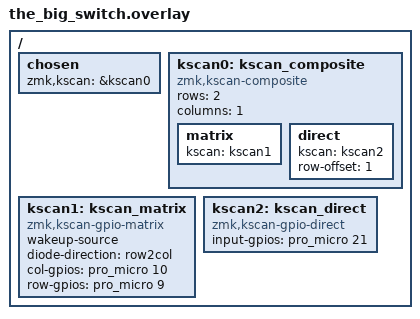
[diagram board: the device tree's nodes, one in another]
/*
 * Copyright (c) 2022 The ZMK Contributors
 *
 * SPDX-License-Identifier: MIT
 */

/ {
    chosen {
        zmk,kscan = &kscan0;
    };

    kscan0: kscan_composite {
        compatible = "zmk,kscan-composite";
        rows = <2>;
        columns = <1>;

        matrix {
            kscan = <&kscan1>;
        };

        direct {
            kscan = <&kscan2>;
            row-offset = <1>;
        };
    };

    kscan1: kscan_matrix {
        compatible = "zmk,kscan-gpio-matrix";
        wakeup-source;
        diode-direction = "row2col";

        col-gpios
            = <&pro_micro 10 (GPIO_ACTIVE_HIGH | GPIO_PULL_DOWN)>
            ;
        row-gpios
            = <&pro_micro 9 GPIO_ACTIVE_HIGH>
            ;
    };

    // mod to have extra button
    kscan2: kscan_direct {
        compatible = "zmk,kscan-gpio-direct";
        input-gpios
            = <&pro_micro 21 (GPIO_ACTIVE_HIGH | GPIO_PULL_DOWN)>
            ;
    };

};
